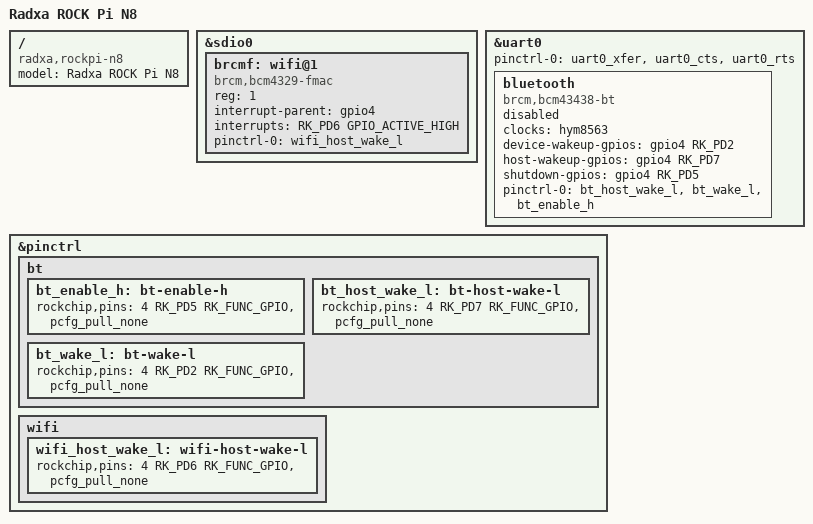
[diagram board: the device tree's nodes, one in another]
// SPDX-License-Identifier: (GPL-2.0+ OR MIT)
/*
 * Copyright (c) 2019 Fuzhou Rockchip Electronics Co., Ltd
 * Copyright (c) 2019 Vamrs Limited
 * Copyright (c) 2019 Amarula Solutions(India)
 */

/dts-v1/;
#include "rk3288.dtsi"
#include <arm/rockchip-radxa-dalang-carrier.dtsi>
#include "rk3288-vmarc-som.dtsi"

/ {
	model = "Radxa ROCK Pi N8";
	compatible = "radxa,rockpi-n8", "vamrs,rk3288-vmarc-som",
		     "rockchip,rk3288";
};

&sdio0 {
	#address-cells = <1>;
	#size-cells = <0>;

	brcmf: wifi@1 {
		compatible = "brcm,bcm4329-fmac";
		reg = <1>;
		interrupt-parent = <&gpio4>;
		interrupts = <RK_PD6 GPIO_ACTIVE_HIGH>;
		interrupt-names = "host-wake";
		pinctrl-names = "default";
		pinctrl-0 = <&wifi_host_wake_l>;
	};
};

&uart0 {
	pinctrl-0 = <&uart0_xfer &uart0_cts &uart0_rts>;

	bluetooth {
		compatible = "brcm,bcm43438-bt";
		clocks = <&hym8563>;
		clock-names = "ext_clock";
		device-wakeup-gpios = <&gpio4 RK_PD2 GPIO_ACTIVE_HIGH>;	/* BT_WAKE */
		host-wakeup-gpios = <&gpio4 RK_PD7 GPIO_ACTIVE_HIGH>;	/* BT_HOST_WAKE */
		shutdown-gpios = <&gpio4 RK_PD5 GPIO_ACTIVE_HIGH>;	/* BT_RST */
		pinctrl-names = "default";
		pinctrl-0 = <&bt_host_wake_l &bt_wake_l &bt_enable_h>;
		status = "disabled";
	};
};

&pinctrl {
	bt {
		bt_enable_h: bt-enable-h {
			rockchip,pins = <4 RK_PD5 RK_FUNC_GPIO &pcfg_pull_none>;
		};

		bt_host_wake_l: bt-host-wake-l {
			rockchip,pins = <4 RK_PD7 RK_FUNC_GPIO &pcfg_pull_none>;
		};

		bt_wake_l: bt-wake-l {
			rockchip,pins = <4 RK_PD2 RK_FUNC_GPIO &pcfg_pull_none>;
		};
	};

	wifi {
		wifi_host_wake_l: wifi-host-wake-l {
			rockchip,pins = <4 RK_PD6 RK_FUNC_GPIO &pcfg_pull_none>;
		};
	};
};
